# K1921VK035 register map
Vendor: NIIET; Series: K1921VKx; File version: 2.10
CPU: CM4 r0p1, little endian, MPU, FPU, 3 interrupt priority bits
Registers are 32-bit, read-write, reset 0x0 unless marked. A register's access mark holds for its fields unless they carry their own. Offsets are from the block's base; [hi:lo] are bit positions; lines under a group give offsets from that group; {n}, {i} and the like mark numbered series.

## SPI — SPI control registers
Base 0x40047000
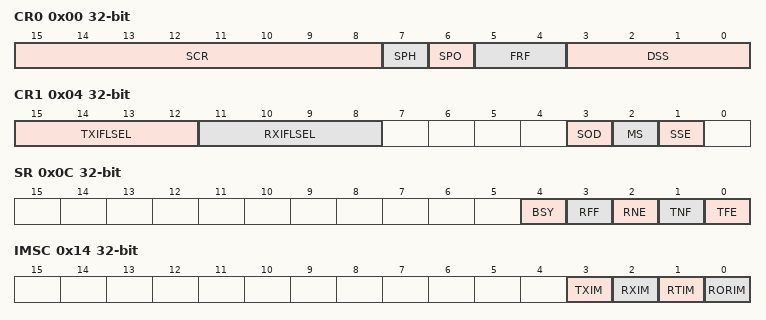
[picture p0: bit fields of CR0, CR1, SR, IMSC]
0x00 CR0 — Control register 0
  [15:8] SCR
  [7] SPH — Phase SSPCLKOUT
  [6] SPO — Polarity SSPCLKOUT
  [5:4] FRF
    0=SPI (SPI of Motorola); 1=SSI (SSI of Texas Instruments); 2=Microwire of National Semiconductor
  [3:0] DSS
    {v}={v+1}bit (data size {v+1} bit) (v=3..15)
0x04 CR1 — Control register 1
  [15:12] TXIFLSEL
  [11:8] RXIFLSEL
  [3] SOD — Disable bit data
  [2] MS — Select mode
  [1] SSE — Enable transceiver
0x08 DR — Data register
  [15:0] DATA
0x0C SR ro — State register
  [4] BSY — Activity flag
  [3] RFF — Indicate full receive buffer
  [2] RNE — Indicate not empty receive buffer
  [1] TNF — Indicator the transmitter FIFO buffer is not full
  [0] TFE — FIFO buffer empty flag transmitter
0x10 CPSR — Clock division factor register
  [7:0] CPSDVSR ro
0x14 IMSC — Mask interrupt register
  [3] TXIM — SSPTXINTR interrupt mask bit to fill 50% or less of the FIFO buffer of the transmitter
  [2] RXIM — SSPRXINTR interrupt mask bit to fill 50% or less of the receiver FIFO buffer
  [1] RTIM — Interrupt mask bit SSPRTINTR timeout receiver
  [0] RORIM — Interrupt mask bit SSPRORINTR buffer overflow receiver
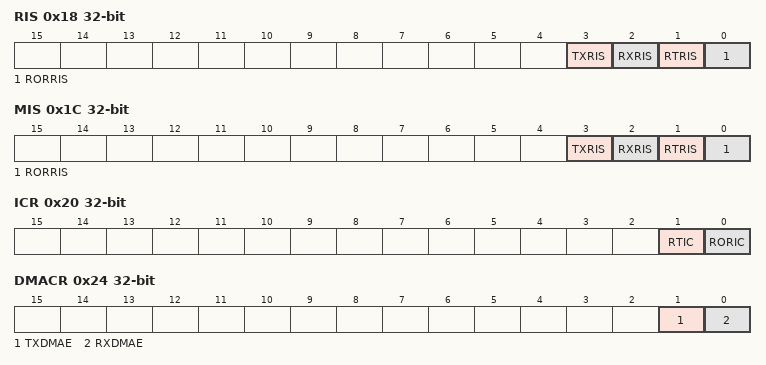
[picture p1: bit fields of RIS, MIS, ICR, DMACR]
0x18 RIS ro — Status register interrupt without mask
  [3] TXRIS — Interrupt status before masking SSPTXINTR
  [2] RXRIS — Interrupt status before masking SSPRXINTR
  [1] RTRIS — Interrupt status before masking SSPRTINTR
  [0] RORRIS — Interrupt status before masking SSPRORINTR
0x1C MIS ro — Status register interrupt masking account
  [3] TXRIS — Masked interrupt status SSPTXINTR
  [2] RXRIS — Masked interrupt status SSPRXINTR
  [1] RTRIS — Masked interrupt status SSPRTINTR
  [0] RORRIS — Masked interrupt status SSPRORINTR
0x20 ICR wo — Register reset interrupt
  [1] RTIC — Reset interrupt SSPRTINTR
  [0] RORIC — Reset interrupt SSPRORINTR
0x24 DMACR — Control register DMA
  [1] TXDMAE — DMA enable bit transmission
  [0] RXDMAE — DMA enable bit at reception

## CANMSG — CAN Msg registers
Base 0x40021000
{0x0+0x20*i} Msg[{i}] (i=0..63) group
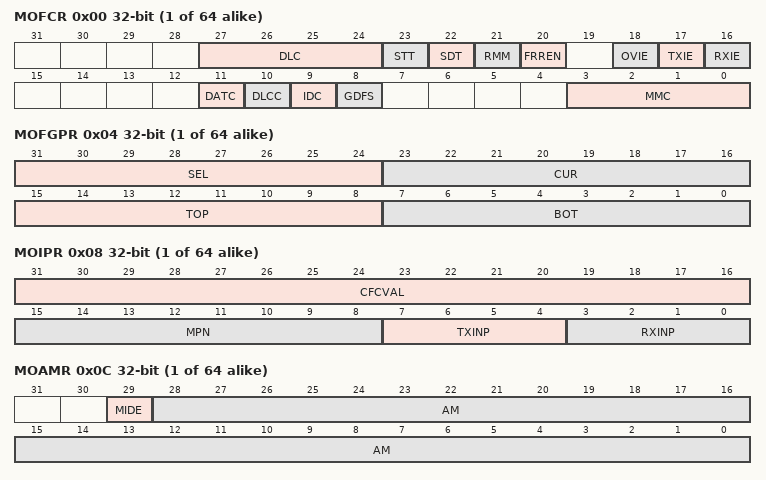
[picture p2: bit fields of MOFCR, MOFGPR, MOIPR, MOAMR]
  0x00 MOFCR — Message Object Function Control Register0
    [27:24] DLC — Data Length Code
    [23] STT — Single Transmit Trial
    [22] SDT — Single Data Transfer
    [21] RMM — Transmit Object Remote Monitoring
    [20] FRREN — Foreign Remote Request Enable
    [18] OVIE — Overflow Interrupt Enable
    [17] TXIE — Transmit Interrupt Enable
    [16] RXIE — Receive Interrupt Enable
    [11] DATC — Data Copy
    [10] DLCC — Data Lengh Code Copy
    [9] IDC — Identifier Copy
    [8] GDFS — Gateway Data Frame Selected
    [3:0] MMC — Message Mode Control
      0=MsgObj (message object); 1=RXObj (receiver FIFO structure object); 2=TXObj (transmitter FIFO structure object); 3=SlaveTXObj (transmitter FIFO structure slave object); 4=SrcObj (gateway source object)
  0x04 MOFGPR — Message Object FIFO/Gateway Pointer Register0
    [31:24] SEL — Object Select Pointer
    [23:16] CUR — Current Object Pointer
    [15:8] TOP — Top Pointer
    [7:0] BOT — Botom Pointer
  0x08 MOIPR — Message Object Interrupt Pointer Register0
    [31:16] CFCVAL — CAN Frame Counter Value
    [15:8] MPN — Message Pending Number
    [7:4] TXINP — Transmit Interrupt Node Pointer
    [3:0] RXINP — Receive Interrupt Node Pointer
  0x0C MOAMR — Message Object Acceptance Mask Register0
    [29] MIDE — Acceptance Mask Bit for Message IDE Bit
    [28:0] AM — Acceptance Mask for Message Identifier
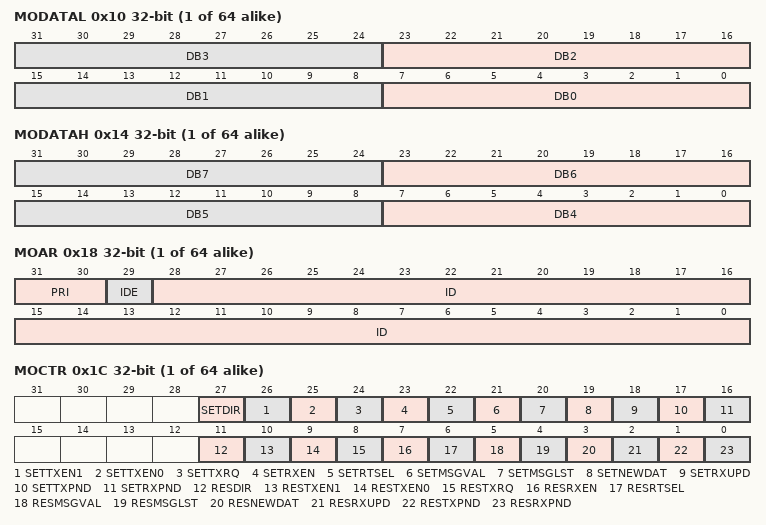
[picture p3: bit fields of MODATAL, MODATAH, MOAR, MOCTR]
  0x10 MODATAL — Message Object Data Register Low0
    [8n+7:8n] DB{n} (n=0..3) — Data byte {n} of message object
  0x14 MODATAH — Message Object Data Register High0
    [8n-25:8n-32] DB{n} (n=4..7) — Data byte {n} of message object
  0x18 MOAR — Message Object Arbitration Register0
    [31:30] PRI — Priority Class
    [29] IDE — Identifier Extension Bit of Messgae Object
    [28:0] ID — CAN identifier of Message Object
  0x1C MOCTR wo — Message Object Control Register0
    [27] SETDIR — Set Message Direction
    [26] SETTXEN1 — Set Transmit Enable 1
    [25] SETTXEN0 — Set Transmit Enable 0
    [24] SETTXRQ — Set Transmit Request
    [23] SETRXEN — Set Receive Enable
    [22] SETRTSEL — Set Receive/Transmit Selected
    [21] SETMSGVAL — Set Message Valid
    [20] SETMSGLST — Set Message Lost
    [19] SETNEWDAT — Set New Data
    [18] SETRXUPD — Set Receive Updating
    [17] SETTXPND — Set Transmit Pending
    [16] SETRXPND — Set Receive Pending
    [11] RESDIR — Reset Message Direction
    [10] RESTXEN1 — Reset Transmit Enable 1
    [9] RESTXEN0 — Reset Transmit Enable 0
    [8] RESTXRQ — Reset Transmit Request
    [7] RESRXEN — Reset Receive Enable
    [6] RESRTSEL — Reset Receive/Transmit Selected
    [5] RESMSGVAL — Reset Message Valid
    [4] RESMSGLST — Reset Message Lost
    [3] RESNEWDAT — Reset New Data
    [2] RESRXUPD — Reset Receive Updating
    [1] RESTXPND — Reset Transmit Pending
    [0] RESRXPND — Reset Receive Pending
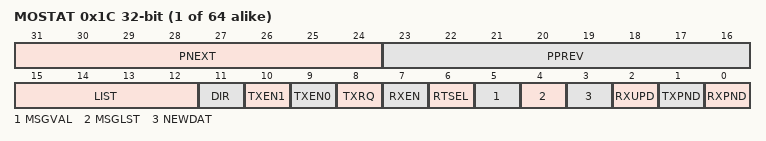
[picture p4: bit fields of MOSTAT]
  0x1C MOSTAT ro (alternate view of MOFCR) — Message Object Status Register 0
    [31:24] PNEXT — Pointer to Next Message Object
    [23:16] PPREV — Pointer To Previous Message Object
    [15:12] LIST — List Allocation
    [11] DIR — Message Direction
    [10] TXEN1 — Transmit Enable 1
    [9] TXEN0 — Transmit Enable 0
    [8] TXRQ — Transmit Request
    [7] RXEN — Receive Enable
    [6] RTSEL — Receive/Transmit Selected
    [5] MSGVAL — Message Valid
    [4] MSGLST — Message Lost
    [3] NEWDAT — New Data
    [2] RXUPD — Receive Updating
    [1] TXPND — Transmit Pending
    [0] RXPND — Receive Pending
